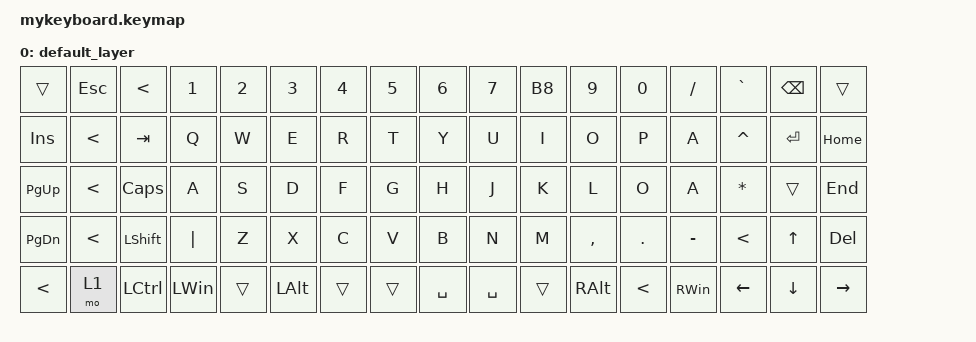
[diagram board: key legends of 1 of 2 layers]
#include <behaviors.dtsi>
#include <dt-bindings/zmk/keys.h>
#include <dt-bindings/zmk/bt.h>

/ {
        keymap {
                compatible = "zmk,keymap";

                default_layer {
// ---------------------------------------------------------------------------------------------------------------------------------------------------
// ||      |  ESC  |  S3    |  1    |  2  |  3    |  4  |  5  |  6      ||    ||  7    |  8  |  9    |  0   |  ?       | ``      |  BSPC   |        ||
// || INS  |  M1   |  TAB   |  Q    |  W  |  E    |  R  |  T  |  Y      ||    ||  U    |  I  |  O    |  P   |  Å       |  ^      |  ENTER  |  HOME  ||
// || PGUP |  M2   |  CAPS  |  A    |  S  |  D    |  F  |  G  |  H      ||    ||  J    |  K  |  L    |  Ö   |  Ä       |  *      |         |  END   ||
// || PGDN |  M3   |  SHFT  |  <    |  Z  |  X    |  C  |  C  |  B      ||    ||  N    |  M  |  ,    | .    |  -       |  SHIFT  |  AR_UP  |  DEL   ||
// || S1   |  M4   |  CTRL  |  WIN  |     |  ALT  |     |     |  SPACE  ||    || SPACE |     |  ALT  |  F1  |  WINDOW  |  AR_L   |  AR_DN  |  AR_R  ||

// trans for |   |


                        bindings = <
   &trans      &kp  ESC  &kp  LT     &kp  N1    &kp  N2  &kp  N3    &kp  N4  &kp  N5  &kp  N6        &kp  N7     &kp  B8  &kp  N9     &kp  N0     &kp  SLASH  &kp  GRAVE  &kp  BSPC   &trans
   &kp  INS    &kp  LT   &kp  TAB    &kp  Q     &kp  W   &kp  E     &kp  R   &kp  T   &kp  Y         &kp  U      &kp  I   &kp  O      &kp  P      &kp  A      &kp  CARET  &kp  ENTER  &kp  HOME
   &kp  PG_UP  &kp  LT   &kp  CLCK   &kp  A     &kp  S   &kp  D     &kp  F   &kp  G   &kp  H         &kp  J      &kp  K   &kp  L      &kp  O      &kp  A      &kp  STAR   &trans      &kp  END
   &kp  PG_DN  &kp  LT   &kp  LSHFT  &kp  PIPE  &kp  Z   &kp  X     &kp  C   &kp  V   &kp  B         &kp  N      &kp  M   &kp  COMMA  &kp  DOT    &kp MINUS   &kp  LT     &kp  UP     &kp  DEL
   &kp  LT     &mo  1     &kp  LCTRL  &kp  LWIN  &trans   &kp  LALT  &trans   &trans   &kp  SPACE     &kp  SPACE  &trans   &kp  RALT   &kp  LT     &kp  RWIN   &kp  LEFT   &kp  DOWN   &kp  RIGHT
                        >;
                };
                lower_layer {
// ------------------------------------------------------------------------------------------------------------
// |       |  BT1  |  BT2  |  BT3  |  BT4  |  BT5  |          |       |       |       |       |       | BTCLR |
// |       |       |       |       |       |       |          |       |       |       |       |       |       |
// |       |       |       | LPAR  | RPAR  |       |          |       | LBKT  | RBKT  |       |       |       |
// |       |       |       |       |       |       |          |       |       |       |       |       |       |
                        bindings = <
   &trans    &bt BT_SEL 0   &bt BT_SEL 1   &bt BT_SEL 2   &bt BT_SEL 3   &bt BT_SEL 4           &trans    &trans    &trans   &trans   &trans  &bt BT_CLR
   &trans    &trans         &trans         &trans         &trans         &trans                 &trans    &trans    &trans   &trans   &trans  &trans
   &trans    &trans         &trans         &kp LPAR       &kp RPAR       &trans                 &trans    &kp LBKT  &kp RBKT &kp MINUS   &kp EQUAL  &trans
   &trans    &trans         &trans         &trans         &trans         &trans                 &trans    &trans    &trans   &trans   &trans  &trans
                        >;
                };
        };
};
